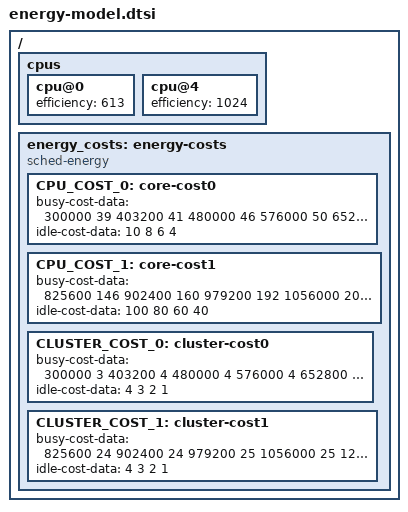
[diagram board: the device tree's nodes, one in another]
/*
 * Auto-generated legacy EAS energy model for incorporation in SoC device tree.
 * Generated by freqbench postprocessing scripts using freqbench results.
 * More info at https://github.com/kdrag0n/freqbench
 */

/ {
	cpus {
		cpu@0 {
			efficiency = <613>;
//			capacity-dmips-mhz = <613>;
		};

		cpu@4 {
			efficiency = <1024>;
//			capacity-dmips-mhz = <1024>;
		};
	};

	energy_costs: energy-costs {
		compatible = "sched-energy";

		CPU_COST_0: core-cost0 {
			busy-cost-data = <
				  300000   39
				  403200   41
				  480000   46
				  576000   50
				  652800   54
				  748800   57
				  825600   69
				  902400   70
				  979200   82
				 1056000   78
				 1132800   94
				 1228800   94
				 1324800  113
				 1420800  105
				 1516800  116
				 1612800  125
				 1689600  129
				 1766400  136
			>;
			idle-cost-data = <
				10 8 6 4
			>;
		};

		CPU_COST_1: core-cost1 {
			busy-cost-data = <
				  825600  146
				  902400  160
				  979200  192
				 1056000  201
				 1209600  223
				 1286400  248
				 1363200  268
				 1459200  297
				 1536000  333
				 1612800  362
				 1689600  400
				 1766400  439
				 1843200  479
				 1920000  498
				 1996800  529
				 2092800  651
				 2169600  653
				 2246400  708
				 2323200  781
				 2400000  784
				 2476800  860
				 2553600  984
				 2649600 1117
				 2803200 1288
			>;
			idle-cost-data = <
				100 80 60 40
			>;
		};

		CLUSTER_COST_0: cluster-cost0 {
			busy-cost-data = <
				 300000    3
				 403200    4
				 480000    4
				 576000    4
				 652800    5
				 748800    5
				 825600    6
				 902400    7
				 979200    7
				 1056000    8
				 1132800    9
				 1228800    9
				 1324800   10
				 1420800   11
				 1516800   12
				 1612800   13
				 1689600   15
				 1766400   17
			>;
			idle-cost-data = <
				4 3 2 1
			>;
		};

		CLUSTER_COST_1: cluster-cost1 {
			busy-cost-data = <
				 825600   24
				 902400   24
				 979200   25
				 1056000   25
				 1209600   26
				 1286400   27
				 1363200   28
				 1459200   29
				 1536000   30
				 1612800   32
				 1689600   34
				 1766400   37
				 1843200   40
				 1920000   45
				 1996800   50
				 2092800   57
				 2169600   64
				 2246400   74
				 2323200   84
				 2400000   96
				 2476800  106
				 2553600  113
				 2649600  120
				 2803200  125
			>;
			idle-cost-data = <
				4 3 2 1
			>;
		};
	};
};
